# TPCC register map
Vendor: Texas Instruments
Peripheral module from a debugger description file (folder awr2544).
Registers are 32-bit, read-only, no defined reset value unless marked. A register's access mark holds for its fields unless they carry their own. Offsets are as the file gives them; lines under a group give offsets from that group; [hi:lo] are bit positions; {n}, {i} and the like mark numbered series; 'fields as' and 'values as' point back to an identical list; <NAME> marks a mode.

## TPCC (part 1 of 2)
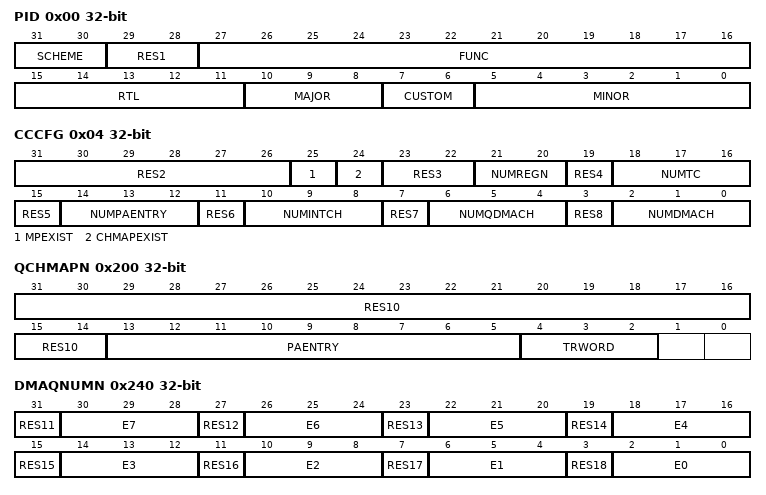
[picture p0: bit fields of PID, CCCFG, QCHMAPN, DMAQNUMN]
0x00 PID — Peripheral ID Register
  [31:30] SCHEME — PID Scheme: Used to distinguish between old ID scheme and current. Spare bit to encode future schemes EDMA uses 'new scheme' indicated with value of 0x1.
  [29:28] RES1 — RESERVE FIELD
  [27:16] FUNC — Function indicates a software compatible module family.
  [15:11] RTL — RTL Version
  [10:8] MAJOR — Major Revision
  [7:6] CUSTOM — Custom revision field: Not used on this version of EDMA.
  [5:0] MINOR — Minor Revision
0x04 CCCFG — CC Configuration Register
  [31:26] RES2 — RESERVE FIELD
  [25] MPEXIST — Memory Protection Existence MPEXIST = 0 : No memory protection. MPEXIST = 1 : Memory Protection logic included.
  [24] CHMAPEXIST — Channel Mapping Existence CHMAPEXIST = 0 : No Channel mapping. CHMAPEXIST = 1 : Channel mapping logic included.
  [23:22] RES3 — RESERVE FIELD
  [21:20] NUMREGN — Number of MP and Shadow regions
  [35-4n] RES{n} (n=4..8) — RESERVE FIELD
  [18:16] NUMTC — Number of Queues/Number of TCs
  [14:12] NUMPAENTRY — Number of PaRAM entries
  [10:8] NUMINTCH — Number of Interrupt Channels
  [6:4] NUMQDMACH — Number of QDMA Channels
  [2:0] NUMDMACH — Number of DMA Channels
0x100 DCHMAPN 14-bit rw — DMA Channel N Mapping to Param Set
  [13:5] PAENTRY — PaRAM Entry number for QDMA Channel N.
0x200 QCHMAPN access per field — QDMA Channel N Mapping Register
  [31:14] RES10 ro — RESERVE FIELD
  [13:5] PAENTRY rw — PaRAM Entry number for QDMA Channel N.
  [4:2] TRWORD rw — TRWORD points to the specific trigger word of the PaRAM Entry defined by PAENTRY. A write to the trigger word results in a QDMA Event being recognized.
0x240 DMAQNUMN access per field — DMA Queue Number Register n Contains the Event queue number to be used for the corresponding DMA Channel.
  [75-4n] RES{n} ro (n=11..18) — RESERVE FIELD
  [4n+2:4n] E{n} rw (n=0..7) — DMA Queue Number for event #{n}
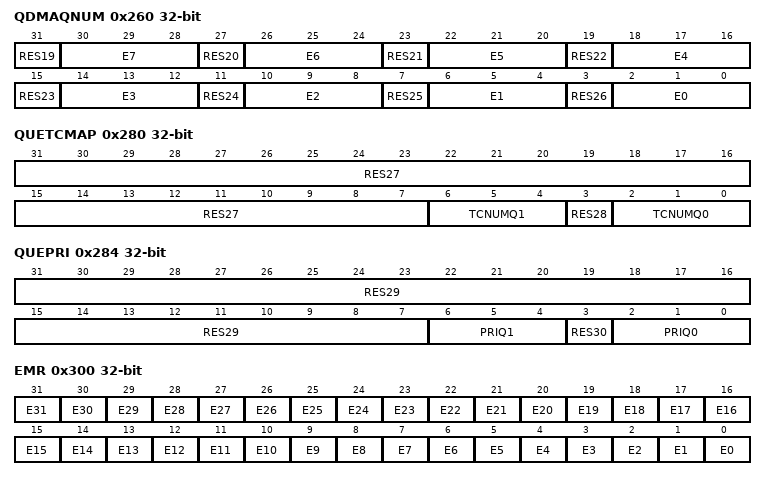
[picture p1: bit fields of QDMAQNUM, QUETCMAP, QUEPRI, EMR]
0x260 QDMAQNUM access per field — QDMA Queue Number Register Contains the Event queue number to be used for the corresponding QDMA Channel.
  [107-4n] RES{n} ro (n=19..26) — RESERVE FIELD
  [4n+2:4n] E{n} rw (n=0..7) — QDMA Queue Number for event #{n}
0x280 QUETCMAP access per field — Queue to TC Mapping
  [31:7] RES27 ro — RESERVE FIELD
  [6:4] TCNUMQ1 rw — TC Number for Queue N: Defines the TC number that Event Queue N TRs are written to.
  [3] RES28 ro — RESERVE FIELD
  [2:0] TCNUMQ0 rw — TC Number for Queue N: Defines the TC number that Event Queue N TRs are written to.
0x284 QUEPRI access per field — Queue Priority
  [31:7] RES29 ro — RESERVE FIELD
  [6:4] PRIQ1 rw — Priority Level for Queue 1 Dictates the priority level used for the OPTIONS field programmation for Qn TRs. Sets the priority used for TC read and write commands.
  [3] RES30 ro — RESERVE FIELD
  [2:0] PRIQ0 rw — Priority Level for Queue 0 Dictates the priority level used for the OPTIONS field programmation for Qn TRs. Sets the priority used for TC read and write commands.
0x300 EMR — Event Missed Register: The Event Missed register is set if 2 events are received without the first event being cleared or if a Null TR is serviced. Chained events (CER) Set Events (ESR) and normal events (ER) are treated individually. If any bit in the EMR register is set (and all errors (including QEMR/CCERR) were previously clear) then an error will be signaled with TPCC error interrupt.
  [n] E{n} (n=0..31) — Event Missed #{n}
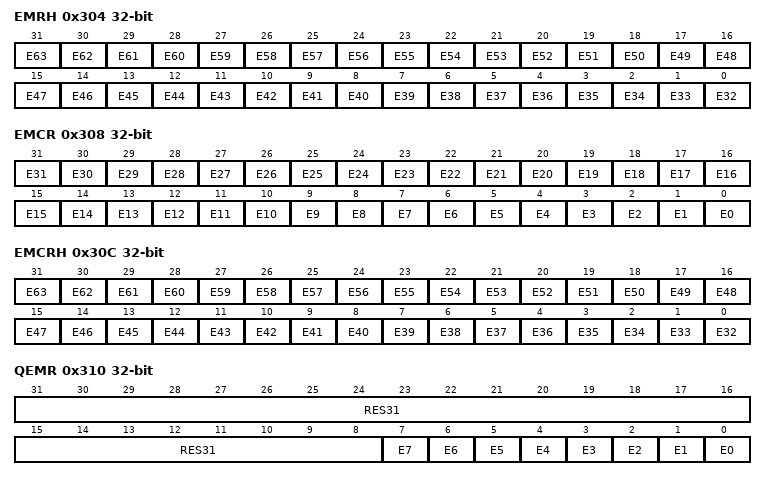
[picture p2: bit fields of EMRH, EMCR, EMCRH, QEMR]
0x304 EMRH — Event Missed Register (High Part): The Event Missed register is set if 2 events are received without the first event being cleared or if a Null TR is serviced. Chained events (CER) Set Events (ESR) and normal events (ER) are treated individually. If any bit in the EMR register is set (and all errors (including QEMR/CCERR) were previously clear) then an error will be signaled with TPCC error interrupt.
  [n-32] E{n} (n=32..63) — Event Missed #{n}
0x308 EMCR wo — Event Missed Clear Register: CPU write of '1' to the EMCR.En bit causes the EMR.En bit to be cleared. CPU write of '0' has no effect.. All error bits must be cleared before additional error interrupts will be asserted by CC.
  [n] E{n} (n=0..31) — Event Missed Clear #{n}
0x30C EMCRH wo — Event Missed Clear Register (High Part): CPU write of '1' to the EMCR.En bit causes the EMR.En bit to be cleared. CPU write of '0' has no effect.. All error bits must be cleared before additional error interrupts will be asserted by CC.
  [n-32] E{n} (n=32..63) — Event Missed Clear #{n}
0x310 QEMR — QDMA Event Missed Register: The QDMA Event Missed register is set if 2 QDMA events are detected without the first event being cleared or if a Null TR is serviced.. If any bit in the QEMR register is set (and all errors (including EMR/CCERR) were previously clear) then an error will be signaled with TPCC error interrupt.
  [31:8] RES31 — RESERVE FIELD
  [n] E{n} (n=0..7) — Event Missed #{n}
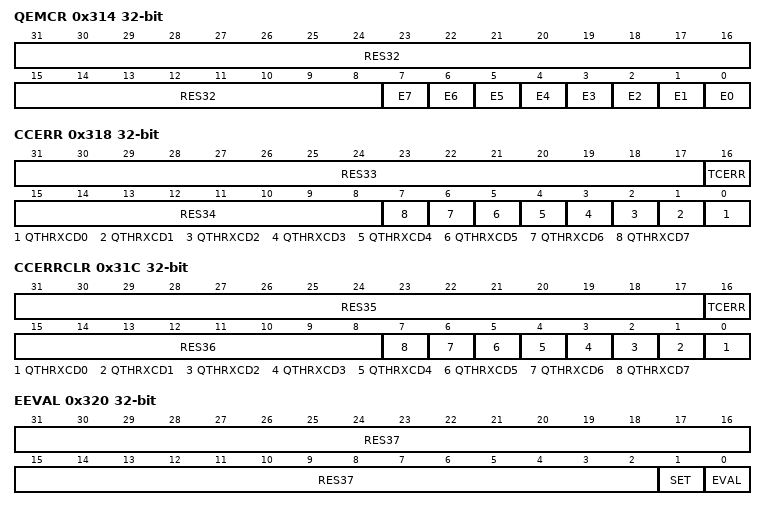
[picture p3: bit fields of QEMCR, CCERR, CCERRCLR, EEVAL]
0x314 QEMCR access per field — QDMA Event Missed Clear Register: CPU write of '1' to the QEMCR.En bit causes the QEMR.En bit to be cleared. CPU write of '0' has no effect.. All error bits must be cleared before additional error interrupts will be asserted by CC.
  [31:8] RES32 ro — RESERVE FIELD
  [n] E{n} wo (n=0..7) — Event Missed Clear #{n}
0x318 CCERR — CC Error Register
  [31:17] RES33 — RESERVE FIELD
  [16] TCERR — Transfer Completion Code Error: TCCERR = 0 : Total number of allowed TCCs outstanding has not been reached. TCCERR = 1 : Total number of allowed TCCs has been reached. TCCERR can be cleared by writing a '1' to corresponding bit in CCERRCLR register. If any bit in the CCERR register is set (and all errors were previously clear) then an error will be signaled with TPCC error interrupt.
  [15:8] RES34 — RESERVE FIELD
  [n] QTHRXCD{n} (n=0..7) — Queue Threshold Error for Q{n}: QTHRXCD{n} = 0 : Watermark/threshold has not been exceeded. QTHRXCD{n} = 1 : Watermark/threshold has been exceeded. CCERR.QTHRXCD{n} can be cleared by writing a '1' to corresponding bit in CCERRCLR register. If any bit in the CCERR register is set (and all errors (including EMR/QEMR) were previously clear) then an error will be signaled with the TPCC error interrupt.
0x31C CCERRCLR access per field — CC Error Clear Register
  [31:17] RES35 ro — RESERVE FIELD
  [16] TCERR wo — Clear Error for CCERR.TCERR: Write of '1' clears the value of CCERR bit N. Writes of '0' have no affect.
  [15:8] RES36 ro — RESERVE FIELD
  [n] QTHRXCD{n} wo (n=0..7) — Clear error for CCERR.QTHRXCD{n}: Write of '1' clears the values of QSTAT{n}.WM QSTAT{n}.THRXCD CCERR.QTHRXCD{n} Writes of '0' have no affect.
0x320 EEVAL access per field — Error Eval Register
  [31:2] RES37 ro — RESERVE FIELD
  [1] SET wo — Error Interrupt Set: CPU write of '1' to the SET bit causes the TPCC error interrupt to be pulsed regardless of state of EMR/EMRH QEMR or CCERR. CPU write of '0' has no effect.
  [0] EVAL wo — Error Interrupt Evaluate: CPU write of '1' to the EVAL bit causes the TPCC error interrupt to be pulsed if any errors have not been cleared in the EMR/EMRH QEMR or CCERR registers. CPU write of '0' has no effect.
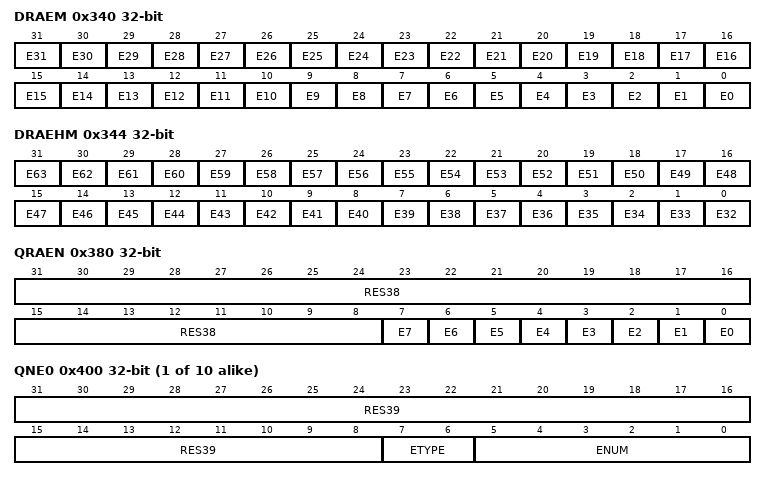
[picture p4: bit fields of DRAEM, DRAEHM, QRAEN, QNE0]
0x340 DRAEM rw — DMA Region Access enable for bit N in Region M: En = 0 : Accesses via Region M address space to Bit N in any DMA Channel Register are not allowed. Reads will return 'b0 on Bit N and writes will not modify the state of bit N. Enabled interrupt bits for bit N do not contribute to the generation of the TPCC region M interrupt. En = 1 : Accesses via Region M address space to Bit N in any DMA Channel Register are allowed. Reads will return the value from Bit N and writes will modify the state of bit N. Enabled interrupt bits for bit N do contribute to the generation of the TPCC region M interrupt.
  [n] E{n} (n=0..31) — DMA Region Access enable for Region M bit #{n}
0x344 DRAEHM rw — DMA Region Access enable for bit N in Region M: En = 0 : Accesses via Region M address space to Bit N in any DMA Channel Register are not allowed. Reads will return 'b0 on Bit N and writes will not modify the state of bit N. Enabled interrupt bits for bit N do not contribute to the generation of the TPCC region M interrupt. En = 1 : Accesses via Region M address space to Bit N in any DMA Channel Register are allowed. Reads will return the value from Bit N and writes will modify the state of bit N. Enabled interrupt bits for bit N do contribute to the generation of the TPCC region M interrupt. En = 0 : Accesses via Region M address space to Bit N in any DMA Channel Register are not allowed. Reads will return 'b0 on Bit N and writes will not modify the state of bit N. Enabled interrupt bits for bit N do not contribute to the generation of the TPCC region M interrupt. En = 1 : Accesses via Region M address space to Bit N in any DMA Channel Register are allowed. Reads will return the value from Bit N and writes will modify the state of bit N. Enabled interrupt bits for bit N do contribute to the generation of the TPCC region M interrupt.
  [n-32] E{n} (n=32..63) — DMA Region Access enable for Region M bit #{n}
0x380 QRAEN access per field — QDMA Region Access enable for bit N in Region M: En = 0 : Accesses via Region M address space to Bit N in any QDMA Channel Register are not allowed. Reads will return 'b0 on Bit N and writes will not modify the state of bit N. Enabled interrupt bits for bit N do not contribute to the generation of the TPCC region M interrupt. En = 1 : Accesses via Region M address space to Bit N in any QDMA Channel Register are allowed. Reads will return the value from Bit N and writes will modify the state of bit N. Enabled interrupt bits for bit N do contribute to the generation of the TPCC region n interrupt.
  [31:8] RES38 ro — RESERVE FIELD
  [n] E{n} rw (n=0..7) — QDMA Region Access enable for Region M bit #{n}
{0x400+4i} QNE{i} (i=0..9) — Event Queue Entry Diagram for Queue n - Entry {i}
  [31:8] RES{i+39} — RESERVE FIELD
  [7:6] ETYPE — Event Type: Specifies the specific Event Type for the given entry in the Event Queue.
  [5:0] ENUM — Event Number: Specifies the specific Event Number for the given entry in the Event Queue. For DMA Channel events (ER/ESR/CER) ENUM will range between 0 and NUM_DMACH (up to 63). For QDMA Channel events (QER) ENUM will range between 0 and NUM_QDMACH (up to 7).
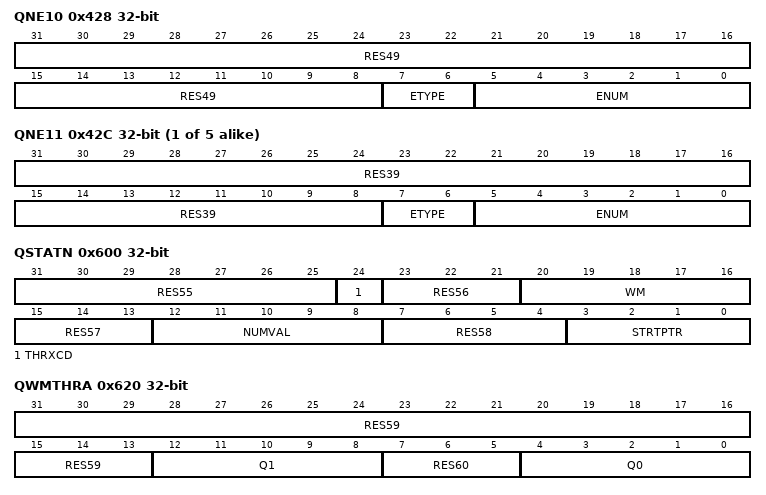
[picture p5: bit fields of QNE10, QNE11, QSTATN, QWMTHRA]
0x428 QNE10 — Event Queue Entry Diagram for Queue n - Entry 0
  [31:8] RES49 — RESERVE FIELD
  [7:6] ETYPE — Event Type: Specifies the specific Event Type for the given entry in the Event Queue.
  [5:0] ENUM — Event Number: Specifies the specific Event Number for the given entry in the Event Queue. For DMA Channel events (ER/ESR/CER) ENUM will range between 0 and NUM_DMACH (up to 63). For QDMA Channel events (QER) ENUM will range between 0 and NUM_QDMACH (up to 7).
{0x400+4i} QNE{i} (i=11..15) — Event Queue Entry Diagram for Queue n - Entry {i}
  fields as QNE0
0x600 QSTATN — QSTATn Register Set
  [31:25] RES55 — RESERVE FIELD
  [24] THRXCD — Threshold Exceeded: THRXCD = 0 : Threshold specified by QWMTHR(A B).Qn has not been exceeded. THRXCD = 1 : Threshold specified by QWMTHR(A B).Qn has been exceeded. QSTATn.THRXCD is cleared via CCERR.WMCLRn bit.
  [23:21] RES56 — RESERVE FIELD
  [20:16] WM — Watermark for Maximum Queue Usage: Watermark tracks the most entries that have been in QueueN since reset or since the last time that the watermark (WM) was cleared. QSTATn.WM is cleared via CCERR.WMCLRn bit. Legal values = 0x0 (empty) to 0x10 (full)
  [15:13] RES57 — RESERVE FIELD
  [12:8] NUMVAL — Number of Valid Entries in QueueN: Represents the total number of entries residing in the Queue Manager FIFO at a given instant. Always enabled. Legal values = 0x0 (empty) to 0x10 (full)
  [7:4] RES58 — RESERVE FIELD
  [3:0] STRTPTR — Start Pointer: Represents the offset to the head entry of QueueN in units of entries. Always enabled. Legal values = 0x0 (0th entry) to 0xF (15th entry)
0x620 QWMTHRA access per field — Queue Threshold A for Q[3:0]: CCERR.QTHRXCDn and QSTATn.THRXCD error bit is set when the number of Events in QueueN at an instant in time (visible via QSTATn.NUMVAL) equals or exceeds the value specified by QWMTHRA.Qn. Legal values = 0x0 (ever used?) to 0x10 (ever full?) A value of 0x11 disables threshold errors.
  [31:13] RES59 ro — RESERVE FIELD
  [12:8] Q1 rw — Queue Threshold for Q1 value
  [7:5] RES60 ro — RESERVE FIELD
  [4:0] Q0 rw — Queue Threshold for Q0 value
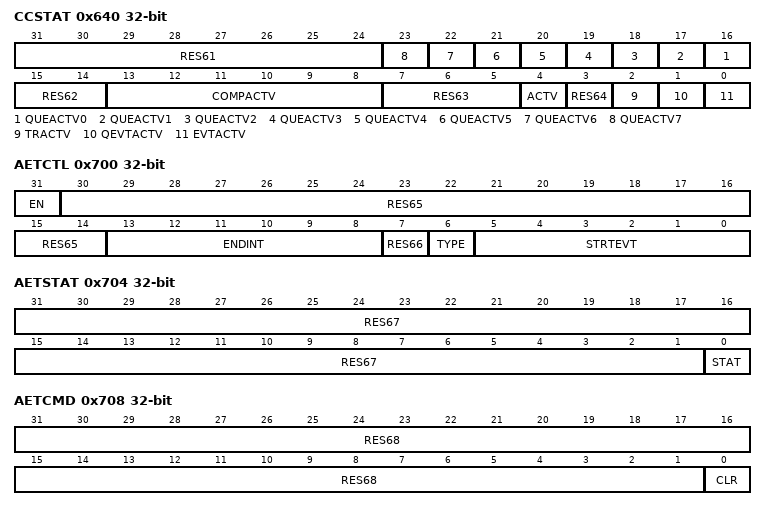
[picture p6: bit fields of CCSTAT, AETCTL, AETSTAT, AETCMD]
0x640 CCSTAT — CC Status Register
  [31:24] RES61 — RESERVE FIELD
  [n+16] QUEACTV{n} (n=0..7) — Queue {n} Active QUEACTV{n} = 0 : No Evts are queued in Q{n}. QUEACTV{n} = 1 : At least one TR is queued in Q{n}.
  [15:14] RES62 — RESERVE FIELD
  [13:8] COMPACTV — Completion Request Active: Counter that tracks the total number of completion requests submitted to the TC. The counter increments when a TR is submitted with TCINTEN or TCCHEN set to '1'. The counter decrements for every valid completion code received from any of the external TCs. The CC will not service new TRs if COMPACTV count is already at the limit. COMPACTV = 0 : No completion requests outstanding. COMPACTV = 1: Total of '1' completion request outstanding. ... COMPACTV = 63 : Total of 63 completion requests are outstanding. No additional TRs will be submitted until count is less than 63.
  [7:5] RES63 — RESERVE FIELD
  [4] ACTV — Channel Controller Active: Channel Controller Active is a logical-OR of each of the ACTV signals. The ACTV bit must remain high through the life of a TR. ACTV = 0 : Channel is idle. ACTV = 1 : Channel is busy.
  [3] RES64 — RESERVE FIELD
  [2] TRACTV — Transfer Request Active: TRACTV = 0 : Transfer Request processing/submission logic is inactive. TRACTV = 1 : Transfer Request processing/submission logic is active.
  [1] QEVTACTV — QDMA Event Active: QEVTACTV = 0 : No enabled QDMA Events are active within the CC. QEVTACTV = 1 : At least one enabled DMA Event (ER & EER ESR CER) is active within the CC.
  [0] EVTACTV — DMA Event Active: EVTACTV = 0 : No enabled DMA Events are active within the CC. EVTACTV = 1 : At least one enabled DMA Event (ER & EER ESR CER) is active within the CC.
0x700 AETCTL access per field — Advanced Event Trigger Control
  [31] EN rw — AET Enable: EN = 0 : AET event generation is disabled. EN = 1 : AET event generation is enabled.
  [30:14] RES65 ro — RESERVE FIELD
  [13:8] ENDINT rw — AET End Interrupt: Dictates the completion interrupt number that will force the tpcc_aet signal to be deasserted (low)
  [7] RES66 ro — RESERVE FIELD
  [6] TYPE rw — AET Event Type: TYPE = 0 : Event specified by STARTEVT applies to DMA Events (set by ER ESR or CER) TYPE = 1 : Event specified by STARTEVT applies to QDMA Events
  [5:0] STRTEVT rw — AET Start Event: Dictates the Event Number that will force the tpcc_aet signal to be asserted (high)
0x704 AETSTAT — Advanced Event Trigger Stat
  [31:1] RES67 — RESERVE FIELD
  [0] STAT — AET Status: AETSTAT = 0 : tpcc_aet is currently low. AETSTAT = 1 : tpcc_aet is currently high.
0x708 AETCMD access per field — AET Command
  [31:1] RES68 ro — RESERVE FIELD
  [0] CLR wo — AET Clear command: CPU write of '1' to the CLR bit causes the tpcc_aet output signal and AETSTAT.STAT register to be cleared. CPU write of '0' has no effect..
0x800 MPFAR — Memory Protect Fault Address
  [31:0] FADDR — Fault Address 32-bit read-only status register containing the faulting address when a memory protection violation is detected. This register can only be cleared via the MPFCR.
0x804 MPFSR 13-bit — Memory Protect Fault Status
  [12:9] FID — Faulted ID FID register contains valid info if any of the MP error bits (UXE, UWE, URE, SXE, SWE, SRE) are non-zero (i.e., if an error has been detected.) The FID field contains the VBus PrivID for the specific request/requestor that resulted in a MP Error.
  [5] SRE — Supervisor Read Error SRE = 0 : No error detected. SRE = 1 : Supervisor level task attempted to Read from a MP Page without SR permissions.
  [4] SWE — Supervisor Write Error SWE = 0 : No error detected. SWE = 1 : Supervisor level task attempted to Write to a MP Page without SW permissions.
  [3] SXE — Supervisor Execute Error SXE = 0 : No error detected. SXE = 1 : Supervisor level task attempted to Execute from a MP Page without SX permissions.
  [2] URE — User Read Error URE = 0 : No error detected. URE = 1 : User level task attempted to Read from a MP Page without UR permissions.
  [1] UWE — User Write Error UWE = 0 : No error detected. UWE = 1 : User level task attempted to Write to a MP Page without UW permissions.
  [0] UXE — User Execute Error UXE = 0 : No error detected. UXE = 1 : User level task attempted to Execute from a MP Page without UX permissions.
0x808 MPFCR access per field — Memory Protect Fault Command
  [0] MPFCLR wo — Fault Clear register CPU write of ‘1’ to the MPFCLR bit causes any error conditions stored in MPFAR and MPFSR registers to be cleared. CPU write of ‘0’ has no effect..
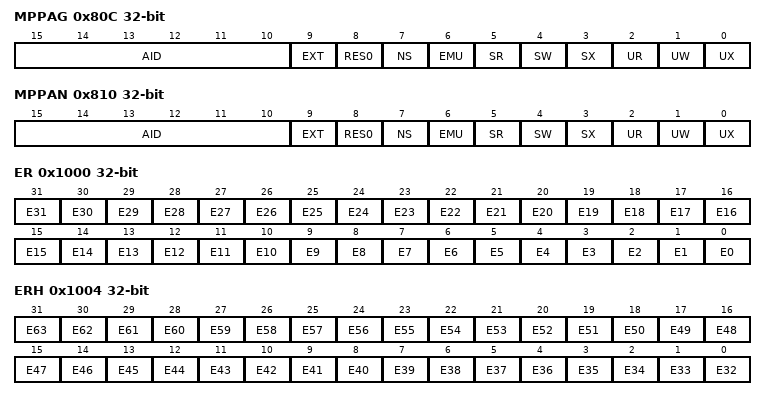
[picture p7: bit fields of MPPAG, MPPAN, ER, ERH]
0x80C MPPAG rw — MP Permission Attribute for Global Regs
  [15:10] AID — Allowed ID ‘M’ AIDm = 0 : VBus requests with PrivID == ‘M’ are not allowed to Region N regardless of permission settings (UW, UR, SW, SR). AIDm = 1 : VBus requests with PrivID == ‘M’ are permitted if access type is allowed as defined by permission settings (UW, UR, SW, SR).
  [9] EXT — External Allowed ID AIDm = 0 : VBus requests with PrivID >= ‘6’ are not allowed to Region N regardless of permission settings (UW, UR, SW, SR). AIDm = 1 : VBus requests with PrivID >= ‘6’ are permitted if access type is allowed as defined by permission settings (UW, UR, SW, SR).
  [8] RES0 — Local accesses (i.e., Link Address updates) are always allowed. LCL bit is not used to allow/disallow Link address updates.
  [7] NS — Secure access permission NS = 0 : Page is secure. Only Secure mode non-emulation accesses may access this page. Emulation accessibility is controlled by EMU setting. NS = 1 : Page is not Secure. Both Secure and Non-secure code may access this page
  [6] EMU — Emulation Security permission EMU = 0 : Emulation (cfg_emudbg == 1) reads/writes to this page are NOT permitted if the page is marked secure (NS = 0). EMU = 1 : Emulation reads/writes to this page ARE permitted.
  [5] SR — Supervisor Read permission SR = 0 : Supervisor read accesses are not allowed from Region N.. SR = 1 : Supervisor write accesses are allowed from Region N addresses
  [4] SW — Supervisor Write permission SW = 0 : Supervisor write accesses are not allowed to Region N.. SW = 1 : Supervisor write accesses are allowed to Region N addresses.
  [3] SX — Supervisor Execute permission SX = 0 : Supervisor execute accesses are not allowed from Region N.. SX = 1 : Supervisor execute accesses are allowed from Region N addresses
  [2] UR — User Read permission UR = 0 : User read accesses are not allowed from Region N.. UR = 1 : User write accesses are allowed from Region N addresses
  [1] UW — User Write permission UW = 0 : User write accesses are not allowed to Region N.. UW = 1 : User write accesses are allowed to Region N addresses.
  [0] UX — User Execute permission UX = 0 : User execute accesses are not allowed from Region N.. UX = 1 : User execute accesses are allowed from Region N addresses.
0x810 MPPAN rw — MP Permission Attribute for DMA Region N starting from 0x810 to 0x82C total 8 regions
  fields as MPPAG
0x1000 ER — Event Register: If ER.En bit is set and the EER.En bit is also set then the corresponding DMA channel is prioritized vs. other pending DMA events for submission to the TC. ER.En bit is set when the input event #n transitions from inactive (low) to active (high) regardless of the state of EER.En bit. ER.En bit is cleared when the corresponding event is prioritized and serviced. If the ER.En bit is already set and a new inactive to active transition is detected on the input event #n input AND the corresponding bit in the EER register is set then the corresponding bit in the Event Missed Register is set. Event N can be cleared via sw by writing a '1' to the ECR pseudo-register.
  [n] E{n} (n=0..31) — Event #{n}
0x1004 ERH — Event Register (High Part): If ERH.En bit is set and the EERH.En bit is also set then the corresponding DMA channel is prioritized vs. other pending DMA events for submission to the TC. ERH.En bit is set when the input event #n transitions from inactive (low) to active (high) regardless of the state of EERH.En bit. ER.En bit is cleared when the corresponding event is prioritized and serviced. If the ERH.En bit is already set and a new inactive to active transition is detected on the input event #n input AND the corresponding bit in the EERH register is set then the corresponding bit in the Event Missed Register is set. Event N can be cleared via sw by writing a '1' to the ECRH pseudo-register.
  [n-32] E{n} (n=32..63) — Event #{n}
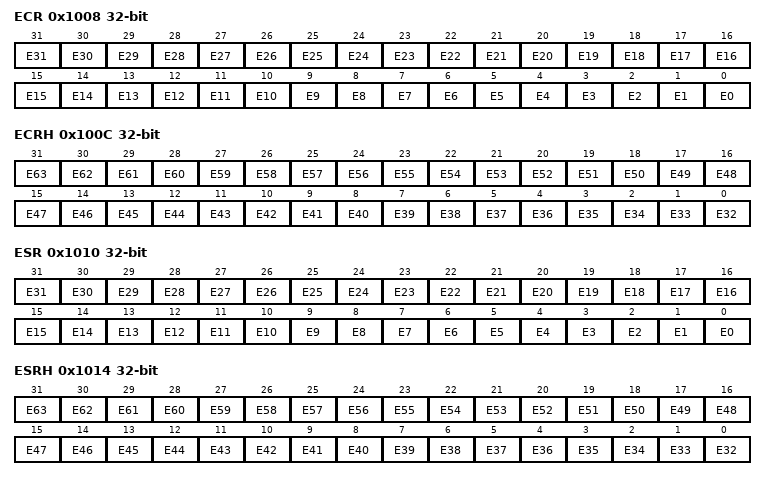
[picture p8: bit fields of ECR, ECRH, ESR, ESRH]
0x1008 ECR wo — Event Clear Register: CPU write of '1' to the ECR.En bit causes the ER.En bit to be cleared. CPU write of '0' has no effect.
  [n] E{n} (n=0..31) — Event #{n}
0x100C ECRH wo — Event Clear Register (High Part): CPU write of '1' to the ECRH.En bit causes the ERH.En bit to be cleared. CPU write of '0' has no effect.
  [n-32] E{n} (n=32..63) — Event #{n}
0x1010 ESR wo — Event Set Register: CPU write of '1' to the ESR.En bit causes the ER.En bit to be set. CPU write of '0' has no effect.
  [n] E{n} (n=0..31) — Event #{n}
0x1014 ESRH wo — Event Set Register (High Part) CPU write of '1' to the ESRH.En bit causes the ERH.En bit to be set. CPU write of '0' has no effect.
  [n-32] E{n} (n=32..63) — Event #{n}
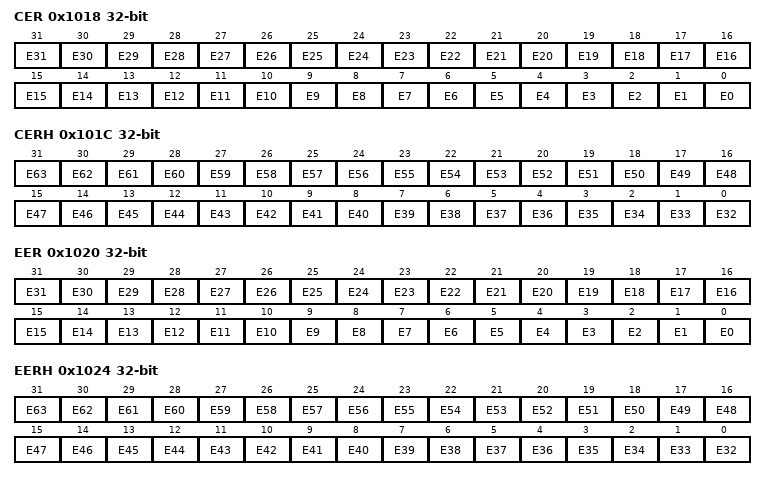
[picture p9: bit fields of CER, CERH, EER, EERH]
0x1018 CER — Chained Event Register: If CER.En bit is set (regardless of state of EER.En) then the corresponding DMA channel is prioritized vs. other pending DMA events for submission to the TC. CER.En bit is set when a chaining completion code is returned from one of the 3PTCs via the completion interface or is generated internally via Early Completion path. CER.En bit is cleared when the corresponding event is prioritized and serviced. If the CER.En bit is already set and the corresponding chaining completion code is returned from the TC then the corresponding bit in the Event Missed Register is set. CER.En cannot be set or cleared via software.
  [n] E{n} (n=0..31) — Event #{n}
0x101C CERH — Chained Event Register (High Part): If CERH.En bit is set (regardless of state of EERH.En) then the corresponding DMA channel is prioritized vs. other pending DMA events for submission to the TC. CERH.En bit is set when a chaining completion code is returned from one of the 3PTCs via the completion interface or is generated internally via Early Completion path. CERH.En bit is cleared when the corresponding event is prioritized and serviced. If the CERH.En bit is already set and the corresponding chaining completion code is returned from the TC then the corresponding bit in the Event Missed Register is set. CERH.En cannot be set or cleared via software.
  [n-32] E{n} (n=32..63) — Event #{n}
0x1020 EER — Event Enable Register: Enables DMA transfers for ER.En pending events. ER.En is set based on externally asserted events (via tpcc_eventN_pi). This register has no effect on Chained Event Register (CER) or Event Set Register (ESR). Note that if a bit is set in ER.En while EER.En is disabled no action is taken. If EER.En is enabled at a later point (and ER.En has not been cleared via SW) then the event will be recognized as a valid 'TR Sync' EER.En is not directly writeable. Events can be enabled via writes to EESR and can be disabled via writes to EECR register. EER.En = 0: ER.En is not enabled to trigger DMA transfers. EER.En = 1: ER.En is enabled to trigger DMA transfers.
  [n] E{n} (n=0..31) — Event #{n}
0x1024 EERH — Event Enable Register (High Part): Enables DMA transfers for ERH.En pending events. ERH.En is set based on externally asserted events (via tpcc_eventN_pi). This register has no effect on Chained Event Register (CERH) or Event Set Register (ESRH). Note that if a bit is set in ERH.En while EERH.En is disabled no action is taken. If EERH.En is enabled at a later point (and ERH.En has not been cleared via SW) then the event will be recognized as a valid 'TR Sync' EERH.En is not directly writeable. Events can be enabled via writes to EESRH and can be disabled via writes to EECRH register. EERH.En = 0: ER.En is not enabled to trigger DMA transfers. EERH.En = 1: ER.En is enabled to trigger DMA transfers.
  [n-32] E{n} (n=32..63) — Event #{n}
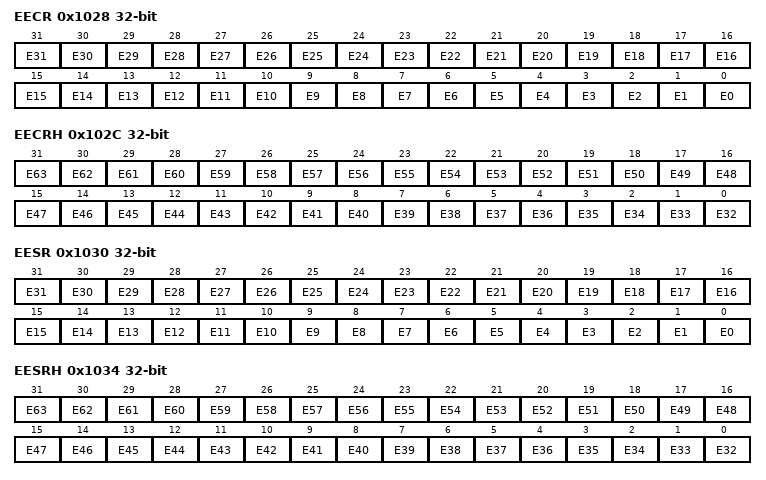
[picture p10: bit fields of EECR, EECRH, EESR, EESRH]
0x1028 EECR wo — Event Enable Clear Register: CPU write of '1' to the EECR.En bit causes the EER.En bit to be cleared. CPU write of '0' has no effect..
  [n] E{n} (n=0..31) — Event #{n}
0x102C EECRH wo — Event Enable Clear Register (High Part): CPU write of '1' to the EECRH.En bit causes the EERH.En bit to be cleared. CPU write of '0' has no effect..
  [n-32] E{n} (n=32..63) — Event #{n}
0x1030 EESR wo — Event Enable Set Register: CPU write of '1' to the EESR.En bit causes the EER.En bit to be set. CPU write of '0' has no effect..
  [n] E{n} (n=0..31) — Event #{n}
0x1034 EESRH wo — Event Enable Set Register (High Part): CPU write of '1' to the EESRH.En bit causes the EERH.En bit to be set. CPU write of '0' has no effect..
  [n-32] E{n} (n=32..63) — Event #{n}
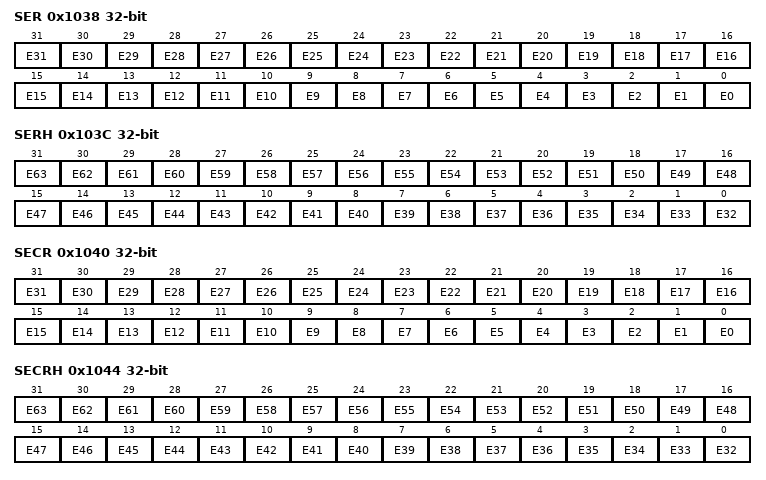
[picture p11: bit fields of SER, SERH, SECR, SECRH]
0x1038 SER — Secondary Event Register: The secondary event register is used along with the Event Register (ER) to provide information on the state of an Event. En = 0 : Event is not currently in the Event Queue. En = 1 : Event is currently stored in Event Queue. Event arbiter will not prioritize additional events.
  [n] E{n} (n=0..31) — Event #{n}
0x103C SERH — Secondary Event Register (High Part): The secondary event register is used along with the Event Register (ERH) to provide information on the state of an Event. En = 0 : Event is not currently in the Event Queue. En = 1 : Event is currently stored in Event Queue. Event arbiter will not prioritize additional events.
  [n-32] E{n} (n=32..63) — Event #{n}
0x1040 SECR wo — Secondary Event Clear Register: The secondary event clear register is used to clear the status of the SER registers. CPU write of '1' to the SECR.En bit clears the SER register. CPU write of '0' has no effect.
  [n] E{n} (n=0..31) — Event #{n}
0x1044 SECRH wo — Secondary Event Clear Register (High Part): The secondary event clear register is used to clear the status of the SERH registers. CPU write of '1' to the SECRH.En bit clears the SERH register. CPU write of '0' has no effect.
  [n-32] E{n} (n=32..63) — Event #{n}
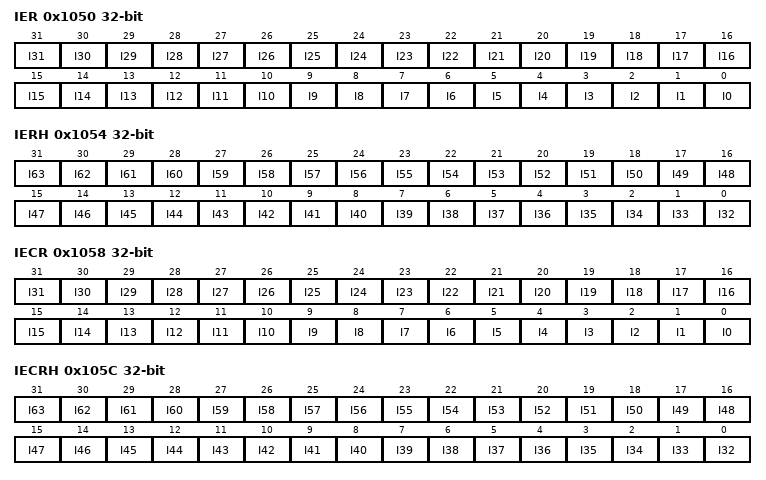
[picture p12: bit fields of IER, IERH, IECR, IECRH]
0x1050 IER — Int Enable Register: IER.In is not directly writeable. Interrupts can be enabled via writes to IESR and can be disabled via writes to IECR register. IER.In = 0: IPR.In is NOT enabled for interrupts. IER.In = 1: IPR.In IS enabled for interrupts.
  [n] I{n} (n=0..31) — Interrupt associated with TCC #{n}
0x1054 IERH — Int Enable Register (High Part): IERH.In is not directly writeable. Interrupts can be enabled via writes to IESRH and can be disabled via writes to IECRH register. IERH.In = 0: IPRH.In is NOT enabled for interrupts. IERH.In = 1: IPRH.In IS enabled for interrupts.
  [n-32] I{n} (n=32..63) — Interrupt associated with TCC #{n}
0x1058 IECR wo — Int Enable Clear Register: CPU write of '1' to the IECR.In bit causes the IER.In bit to be cleared. CPU write of '0' has no effect..
  [n] I{n} (n=0..31) — Interrupt associated with TCC #{n}
0x105C IECRH wo — Int Enable Clear Register (High Part): CPU write of '1' to the IECRH.In bit causes the IERH.In bit to be cleared. CPU write of '0' has no effect..
  [n-32] I{n} (n=32..63) — Interrupt associated with TCC #{n}
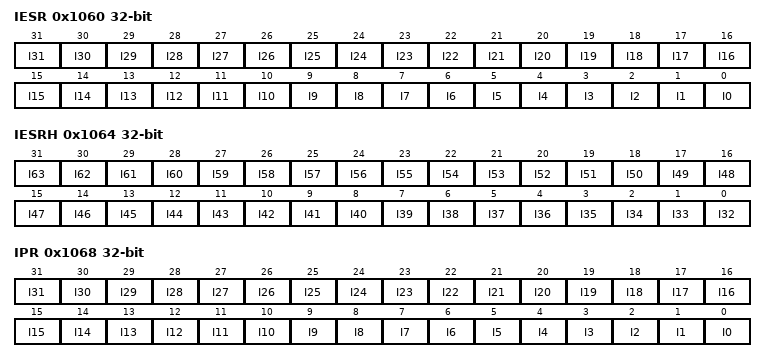
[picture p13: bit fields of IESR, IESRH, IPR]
0x1060 IESR wo — Int Enable Set Register: CPU write of '1' to the IESR.In bit causes the IESR.In bit to be set. CPU write of '0' has no effect..
  [n] I{n} (n=0..31) — Interrupt associated with TCC #{n}
0x1064 IESRH wo — Int Enable Set Register (High Part): CPU write of '1' to the IESRH.In bit causes the IESRH.In bit to be set. CPU write of '0' has no effect..
  [n-32] I{n} (n=32..63) — Interrupt associated with TCC #{n}
0x1068 IPR — Interrupt Pending Register: IPR.In bit is set when a interrupt completion code with TCC of N is detected. IPR.In bit is cleared via software by writing a '1' to ICR.In bit.
  [n] I{n} (n=0..31) — Interrupt associated with TCC #{n}
